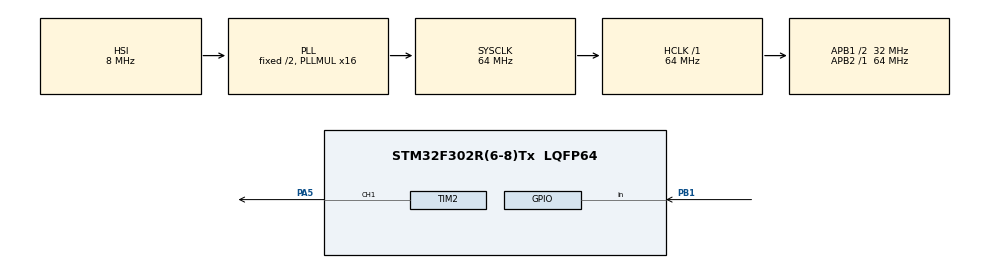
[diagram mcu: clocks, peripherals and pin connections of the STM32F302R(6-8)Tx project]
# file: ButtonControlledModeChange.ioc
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Mcu.Family=STM32F3
Mcu.Name=STM32F302R(6-8)Tx
Mcu.Package=LQFP64
NVIC.PriorityGroup=NVIC_PRIORITYGROUP_0
NVIC.TIM2_IRQn=true\:0\:0\:false\:false\:true\:true\:true\:true
PA5.Signal=S_TIM2_CH1_ETR
PB1.Signal=GPIO_Input
ProjectManager.HeapSize=0x200
ProjectManager.StackSize=0x400
ProjectManager.TargetToolchain=STM32CubeIDE
RCC.AHBFreq_Value=64000000
RCC.APB1CLKDivider=RCC_HCLK_DIV2
RCC.APB1Freq_Value=32000000
RCC.APB1TimFreq_Value=64000000
RCC.APB2Freq_Value=64000000
RCC.APB2TimFreq_Value=64000000
RCC.CortexFreq_Value=64000000
RCC.HCLKFreq_Value=64000000
RCC.HSE_VALUE=8000000
RCC.HSI_VALUE=8000000
RCC.LSE_VALUE=32768
RCC.PLLM=8
RCC.PLLMUL=RCC_PLL_MUL16
RCC.PLLN=336
RCC.PLLP=RCC_PLLP_DIV4
RCC.PLLQ=7
RCC.RCC_PLLsource_Clock_Source_FROM_HSE=RCC_HSE_PREDIV_DIV2
RCC.SYSCLKFreq_VALUE=64000000
RCC.SYSCLKSourceVirtual=RCC_SYSCLKSOURCE_PLLCLK
RCC.USBFreq_Value=64000000
SH.S_TIM2_CH1_ETR.0=TIM2_CH1,PWM Generation1 CH1
TIM2.AutoReloadPreload=TIM_AUTORELOAD_PRELOAD_DISABLE
TIM2.Channel-PWM\ Generation1\ CH1=TIM_CHANNEL_1
TIM2.Period=1000
TIM2.Prescaler=63
VP_TIM2_VS_ClockSourceINT.Mode=Internal
board=NUCLEO-F302R8

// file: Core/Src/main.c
/* USER CODE BEGIN Header */
/**
  ******************************************************************************
  * @file           : main.c
  * @brief          : Main program body
  ******************************************************************************
  * @attention
  *
  * Copyright (c) 2025 STMicroelectronics.
  * All rights reserved.
  *
  * This software is licensed under terms that can be found in the LICENSE file
  * in the root directory of this software component.
  * If no LICENSE file comes with this software, it is provided AS-IS.
  *
  ******************************************************************************
  */
/* USER CODE END Header */
#include "main.h"

TIM_HandleTypeDef htim2;

void SystemClock_Config(void);
static void MX_GPIO_Init(void);
static void MX_TIM2_Init(void);

/* USER CODE BEGIN 0 */
uint8_t mode = 0;
uint8_t button_sit = 0;
uint32_t last_time = 0;
uint8_t max_mode = 3;
//mode 0 = closed
//mode 1 = low light
//mode 2 = high light
//mode 3 = blinking
/* USER CODE END 0 */

int main(void)
{

  /* MCU Configuration--------------------------------------------------------*/

  /* Reset of all peripherals, Initializes the Flash interface and the Systick. */
  HAL_Init();

  /* Configure the system clock */
  SystemClock_Config();

  /* Initialize all configured peripherals */
  MX_GPIO_Init();
  MX_TIM2_Init();

  /* Infinite loop */
  /* USER CODE BEGIN WHILE */
  while (1)
  {
	  button_sit = HAL_GPIO_ReadPin(GPIOB, GPIO_PIN_1);
	  	  if(button_sit){
	  		  if(HAL_GetTick() - last_time >= 200){
	  			  if(mode < max_mode){
	  				  mode += 1;
	  			  }
	  			  else if(mode >= max_mode){
	  				  mode = 0;
	  			  }
	  			  last_time = HAL_GetTick();
	  		  }
	  	  }

	  	  switch(mode)
	  	  {
	  	  case 0:
	  		  HAL_TIM_Base_Stop_IT(&htim2);
	  		  HAL_TIM_PWM_Start(&htim2, TIM_CHANNEL_1);
	  		  __HAL_TIM_SET_PRESCALER(&htim2, 63);
	  		  __HAL_TIM_SET_COMPARE(&htim2, TIM_CHANNEL_1, 0);
	  		  break;
	  	  case 1:
	  		  __HAL_TIM_SET_COMPARE(&htim2, TIM_CHANNEL_1, 100);
	  		  break;
	  	  case 2:
	  		  __HAL_TIM_SET_COMPARE(&htim2, TIM_CHANNEL_1, 900);
	  		  break;
	  	  case 3:
	  		  HAL_TIM_Base_Start_IT(&htim2);
	  		  __HAL_TIM_SET_PRESCALER(&htim2, 63000);
	  		  break;
	  	  }

    /* USER CODE END WHILE */

  }
}

void SystemClock_Config(void)
{
  RCC_OscInitTypeDef RCC_OscInitStruct = {0};
  RCC_ClkInitTypeDef RCC_ClkInitStruct = {0};

  /** Initializes the RCC Oscillators according to the specified parameters
  * in the RCC_OscInitTypeDef structure.
  */
  RCC_OscInitStruct.OscillatorType = RCC_OSCILLATORTYPE_HSI;
  RCC_OscInitStruct.HSIState = RCC_HSI_ON;
  RCC_OscInitStruct.HSICalibrationValue = RCC_HSICALIBRATION_DEFAULT;
  RCC_OscInitStruct.PLL.PLLState = RCC_PLL_ON;
  RCC_OscInitStruct.PLL.PLLSource = RCC_PLLSOURCE_HSI;
  RCC_OscInitStruct.PLL.PLLMUL = RCC_PLL_MUL16;
  if (HAL_RCC_OscConfig(&RCC_OscInitStruct) != HAL_OK)
  {
    Error_Handler();
  }

  /** Initializes the CPU, AHB and APB buses clocks
  */
  RCC_ClkInitStruct.ClockType = RCC_CLOCKTYPE_HCLK|RCC_CLOCKTYPE_SYSCLK
                              |RCC_CLOCKTYPE_PCLK1|RCC_CLOCKTYPE_PCLK2;
  RCC_ClkInitStruct.SYSCLKSource = RCC_SYSCLKSOURCE_PLLCLK;
  RCC_ClkInitStruct.AHBCLKDivider = RCC_SYSCLK_DIV1;
  RCC_ClkInitStruct.APB1CLKDivider = RCC_HCLK_DIV2;
  RCC_ClkInitStruct.APB2CLKDivider = RCC_HCLK_DIV1;

  if (HAL_RCC_ClockConfig(&RCC_ClkInitStruct, FLASH_LATENCY_2) != HAL_OK)
  {
    Error_Handler();
  }
}

static void MX_TIM2_Init(void)
{

  TIM_ClockConfigTypeDef sClockSourceConfig = {0};
  TIM_MasterConfigTypeDef sMasterConfig = {0};
  TIM_OC_InitTypeDef sConfigOC = {0};

  htim2.Instance = TIM2;
  htim2.Init.Prescaler = 63;
  htim2.Init.CounterMode = TIM_COUNTERMODE_UP;
  htim2.Init.Period = 1000;
  htim2.Init.ClockDivision = TIM_CLOCKDIVISION_DIV1;
  htim2.Init.AutoReloadPreload = TIM_AUTORELOAD_PRELOAD_DISABLE;
  if (HAL_TIM_Base_Init(&htim2) != HAL_OK)
  {
    Error_Handler();
  }
  sClockSourceConfig.ClockSource = TIM_CLOCKSOURCE_INTERNAL;
  if (HAL_TIM_ConfigClockSource(&htim2, &sClockSourceConfig) != HAL_OK)
  {
    Error_Handler();
  }
  if (HAL_TIM_PWM_Init(&htim2) != HAL_OK)
  {
    Error_Handler();
  }
  sMasterConfig.MasterOutputTrigger = TIM_TRGO_RESET;
  sMasterConfig.MasterSlaveMode = TIM_MASTERSLAVEMODE_DISABLE;
  if (HAL_TIMEx_MasterConfigSynchronization(&htim2, &sMasterConfig) != HAL_OK)
  {
    Error_Handler();
  }
  sConfigOC.OCMode = TIM_OCMODE_PWM1;
  sConfigOC.Pulse = 0;
  sConfigOC.OCPolarity = TIM_OCPOLARITY_HIGH;
  sConfigOC.OCFastMode = TIM_OCFAST_DISABLE;
  if (HAL_TIM_PWM_ConfigChannel(&htim2, &sConfigOC, TIM_CHANNEL_1) != HAL_OK)
  {
    Error_Handler();
  }
  HAL_TIM_MspPostInit(&htim2);

}

static void MX_GPIO_Init(void)
{
  GPIO_InitTypeDef GPIO_InitStruct = {0};

  /* GPIO Ports Clock Enable */
  __HAL_RCC_GPIOA_CLK_ENABLE();
  __HAL_RCC_GPIOB_CLK_ENABLE();

  /*Configure GPIO pin : PB1 */
  GPIO_InitStruct.Pin = GPIO_PIN_1;
  GPIO_InitStruct.Mode = GPIO_MODE_INPUT;
  GPIO_InitStruct.Pull = GPIO_NOPULL;
  HAL_GPIO_Init(GPIOB, &GPIO_InitStruct);

}

/* USER CODE BEGIN 4 */
void HAL_TIM_PeriodElapsedCallback(TIM_HandleTypeDef *htim){
	if(htim->Instance==TIM2){
		HAL_GPIO_TogglePin(GPIOA, GPIO_PIN_5);
	}

}
/* USER CODE END 4 */

void Error_Handler(void)
{
  __disable_irq();
  while (1)
  {
  }
}
